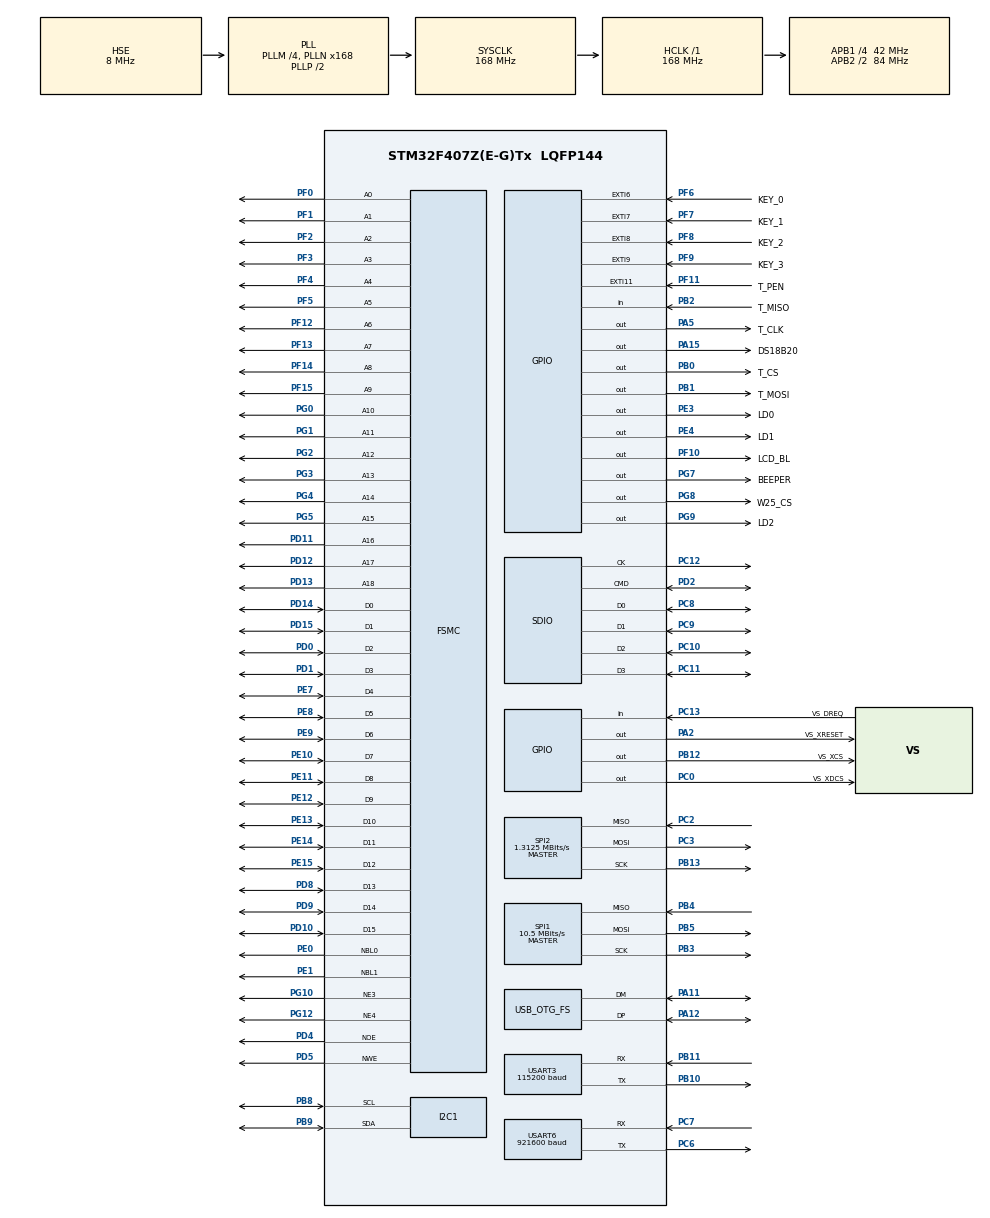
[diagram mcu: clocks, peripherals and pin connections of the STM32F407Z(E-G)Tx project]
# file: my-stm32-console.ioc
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ADC1.Channel-0\#ChannelRegularConversion=ADC_CHANNEL_TEMPSENSOR
ADC1.NbrOfConversionFlag=1
ADC1.Rank-0\#ChannelRegularConversion=1
ADC1.SamplingTime-0\#ChannelRegularConversion=ADC_SAMPLETIME_480CYCLES
ADC1.master=1
Dma.MEMTOMEM.0.Direction=DMA_MEMORY_TO_MEMORY
Dma.MEMTOMEM.0.FIFOMode=DMA_FIFOMODE_ENABLE
Dma.MEMTOMEM.0.FIFOThreshold=DMA_FIFO_THRESHOLD_FULL
Dma.MEMTOMEM.0.Instance=DMA2_Stream0
Dma.MEMTOMEM.0.MemBurst=DMA_MBURST_SINGLE
Dma.MEMTOMEM.0.MemDataAlignment=DMA_MDATAALIGN_HALFWORD
Dma.MEMTOMEM.0.MemInc=DMA_MINC_DISABLE
Dma.MEMTOMEM.0.Mode=DMA_NORMAL
Dma.MEMTOMEM.0.PeriphBurst=DMA_PBURST_SINGLE
Dma.MEMTOMEM.0.PeriphDataAlignment=DMA_PDATAALIGN_HALFWORD
Dma.MEMTOMEM.0.PeriphInc=DMA_PINC_ENABLE
Dma.MEMTOMEM.0.Priority=DMA_PRIORITY_LOW
Dma.Request0=MEMTOMEM
Dma.Request1=SDIO_RX
Dma.Request2=SDIO_TX
Dma.Request3=USART6_RX
Dma.Request4=USART6_TX
Dma.Request5=SPI2_TX
Dma.SDIO_RX.1.Direction=DMA_PERIPH_TO_MEMORY
Dma.SDIO_RX.1.FIFOMode=DMA_FIFOMODE_ENABLE
Dma.SDIO_RX.1.FIFOThreshold=DMA_FIFO_THRESHOLD_FULL
Dma.SDIO_RX.1.Instance=DMA2_Stream3
Dma.SDIO_RX.1.MemBurst=DMA_MBURST_INC4
Dma.SDIO_RX.1.MemDataAlignment=DMA_MDATAALIGN_WORD
Dma.SDIO_RX.1.MemInc=DMA_MINC_ENABLE
Dma.SDIO_RX.1.Mode=DMA_PFCTRL
Dma.SDIO_RX.1.PeriphBurst=DMA_PBURST_INC4
Dma.SDIO_RX.1.PeriphDataAlignment=DMA_PDATAALIGN_WORD
Dma.SDIO_RX.1.PeriphInc=DMA_PINC_DISABLE
Dma.SDIO_RX.1.Priority=DMA_PRIORITY_VERY_HIGH
Dma.SDIO_TX.2.Direction=DMA_MEMORY_TO_PERIPH
Dma.SDIO_TX.2.FIFOMode=DMA_FIFOMODE_ENABLE
Dma.SDIO_TX.2.FIFOThreshold=DMA_FIFO_THRESHOLD_FULL
Dma.SDIO_TX.2.Instance=DMA2_Stream6
Dma.SDIO_TX.2.MemBurst=DMA_MBURST_INC4
Dma.SDIO_TX.2.MemDataAlignment=DMA_MDATAALIGN_WORD
Dma.SDIO_TX.2.MemInc=DMA_MINC_ENABLE
Dma.SDIO_TX.2.Mode=DMA_PFCTRL
Dma.SDIO_TX.2.PeriphBurst=DMA_PBURST_INC4
Dma.SDIO_TX.2.PeriphDataAlignment=DMA_PDATAALIGN_WORD
Dma.SDIO_TX.2.PeriphInc=DMA_PINC_DISABLE
Dma.SDIO_TX.2.Priority=DMA_PRIORITY_VERY_HIGH
Dma.SPI2_TX.5.Direction=DMA_MEMORY_TO_PERIPH
Dma.SPI2_TX.5.FIFOMode=DMA_FIFOMODE_DISABLE
Dma.SPI2_TX.5.Instance=DMA1_Stream4
Dma.SPI2_TX.5.MemDataAlignment=DMA_MDATAALIGN_BYTE
Dma.SPI2_TX.5.MemInc=DMA_MINC_ENABLE
Dma.SPI2_TX.5.Mode=DMA_NORMAL
Dma.SPI2_TX.5.PeriphDataAlignment=DMA_PDATAALIGN_BYTE
Dma.SPI2_TX.5.PeriphInc=DMA_PINC_DISABLE
Dma.SPI2_TX.5.Priority=DMA_PRIORITY_LOW
Dma.USART6_RX.3.Direction=DMA_PERIPH_TO_MEMORY
Dma.USART6_RX.3.FIFOMode=DMA_FIFOMODE_DISABLE
Dma.USART6_RX.3.Instance=DMA2_Stream1
Dma.USART6_RX.3.MemDataAlignment=DMA_MDATAALIGN_BYTE
Dma.USART6_RX.3.MemInc=DMA_MINC_ENABLE
Dma.USART6_RX.3.Mode=DMA_CIRCULAR
Dma.USART6_RX.3.PeriphDataAlignment=DMA_PDATAALIGN_BYTE
Dma.USART6_RX.3.PeriphInc=DMA_PINC_DISABLE
Dma.USART6_RX.3.Priority=DMA_PRIORITY_HIGH
Dma.USART6_TX.4.Direction=DMA_MEMORY_TO_PERIPH
Dma.USART6_TX.4.FIFOMode=DMA_FIFOMODE_DISABLE
Dma.USART6_TX.4.Instance=DMA2_Stream7
Dma.USART6_TX.4.MemDataAlignment=DMA_MDATAALIGN_BYTE
Dma.USART6_TX.4.MemInc=DMA_MINC_ENABLE
Dma.USART6_TX.4.Mode=DMA_NORMAL
Dma.USART6_TX.4.PeriphDataAlignment=DMA_PDATAALIGN_BYTE
Dma.USART6_TX.4.PeriphInc=DMA_PINC_DISABLE
Dma.USART6_TX.4.Priority=DMA_PRIORITY_MEDIUM
FATFS._FS_LOCK=8
FATFS._USE_LFN=2
FREERTOS.HEAP_NUMBER=5
FREERTOS.Tasks01=defaultTask,24,1024,StartDefaultTask,Default,NULL,Dynamic,NULL,NULL
FREERTOS.configCHECK_FOR_STACK_OVERFLOW=2
FREERTOS.configENABLE_FPU=1
FREERTOS.configGENERATE_RUN_TIME_STATS=1
FREERTOS.configUSE_APPLICATION_TASK_TAG=1
FREERTOS.configUSE_STATS_FORMATTING_FUNCTIONS=1
FSMC.AddressSetupTime1=2
FSMC.AddressSetupTime3=3
FSMC.BusTurnAroundDuration1=3
FSMC.BusTurnAroundDuration3=3
FSMC.DataSetupTime1=6
FSMC.DataSetupTime3=12
FSMC.WriteOperation3=FSMC_WRITE_OPERATION_ENABLE
IWDG.Prescaler=IWDG_PRESCALER_32
IWDG.Reload=4095
Mcu.Family=STM32F4
Mcu.Name=STM32F407Z(E-G)Tx
Mcu.Package=LQFP144
NVIC.DMA1_Stream4_IRQn=true\:5\:0\:false\:false\:true\:true\:false\:true\:true
NVIC.DMA2_Stream0_IRQn=true\:5\:0\:false\:false\:true\:true\:true\:true\:true
NVIC.DMA2_Stream1_IRQn=true\:5\:0\:false\:false\:true\:true\:false\:true\:true
NVIC.DMA2_Stream3_IRQn=true\:5\:0\:false\:false\:true\:true\:false\:true\:true
NVIC.DMA2_Stream6_IRQn=true\:5\:0\:false\:false\:true\:true\:false\:true\:true
NVIC.DMA2_Stream7_IRQn=true\:5\:0\:false\:false\:true\:true\:false\:true\:true
NVIC.EXTI15_10_IRQn=true\:5\:0\:false\:false\:true\:true\:true\:true\:true
NVIC.EXTI9_5_IRQn=true\:5\:0\:false\:false\:true\:true\:true\:false\:true
NVIC.OTG_FS_IRQn=true\:6\:0\:true\:false\:true\:true\:true\:true\:true
NVIC.PriorityGroup=NVIC_PRIORITYGROUP_4
NVIC.SDIO_IRQn=true\:5\:0\:false\:false\:true\:true\:true\:true\:true
NVIC.TIM4_IRQn=true\:1\:0\:true\:false\:true\:false\:false\:true\:true
NVIC.TimeBase=TIM4_IRQn
NVIC.TimeBaseIP=TIM4
NVIC.USART3_IRQn=true\:5\:0\:false\:false\:true\:true\:true\:true\:true
NVIC.USART6_IRQn=true\:5\:0\:false\:false\:true\:true\:true\:true\:true
PA11.Mode=Host_Only
PA11.Signal=USB_OTG_FS_DM
PA12.Mode=Host_Only
PA12.Signal=USB_OTG_FS_DP
PA13.Mode=Serial_Wire
PA13.Signal=SYS_JTMS-SWDIO
PA14.Mode=Serial_Wire
PA14.Signal=SYS_JTCK-SWCLK
PA15.GPIO_Label=DS18B20
PA15.Signal=GPIO_Output
PA2.GPIO_Label=VS_XRESET
PA2.Signal=GPIO_Output
PA5.GPIO_Label=T_CLK
PA5.PinState=GPIO_PIN_SET
PA5.Signal=GPIO_Output
PB0.GPIO_Label=T_CS
PB0.PinState=GPIO_PIN_SET
PB0.Signal=GPIO_Output
PB1.GPIO_Label=T_MOSI
PB1.PinState=GPIO_PIN_SET
PB1.Signal=GPIO_Output
PB10.Mode=Asynchronous
PB10.Signal=USART3_TX
PB11.Mode=Asynchronous
PB11.Signal=USART3_RX
PB12.GPIO_Label=VS_XCS
PB12.GPIO_Speed=GPIO_SPEED_FREQ_HIGH
PB12.PinState=GPIO_PIN_SET
PB12.Signal=GPIO_Output
PB13.Mode=Full_Duplex_Master
PB13.Signal=SPI2_SCK
PB2.GPIO_Label=T_MISO
PB2.GPIO_PuPd=GPIO_PULLUP
PB2.Signal=GPIO_Input
PB3.Mode=Full_Duplex_Master
PB3.Signal=SPI1_SCK
PB4.Mode=Full_Duplex_Master
PB4.Signal=SPI1_MISO
PB5.Mode=Full_Duplex_Master
PB5.Signal=SPI1_MOSI
PB8.Mode=I2C
PB8.Signal=I2C1_SCL
PB9.Mode=I2C
PB9.Signal=I2C1_SDA
PC0.GPIO_Label=VS_XDCS
PC0.GPIO_Speed=GPIO_SPEED_FREQ_HIGH
PC0.PinState=GPIO_PIN_SET
PC0.Signal=GPIO_Output
PC10.Mode=SD_4_bits_Wide_bus
PC10.Signal=SDIO_D2
PC11.Mode=SD_4_bits_Wide_bus
PC11.Signal=SDIO_D3
PC12.Mode=SD_4_bits_Wide_bus
PC12.Signal=SDIO_CK
PC13-ANTI_TAMP.GPIO_Label=VS_DREQ
PC13-ANTI_TAMP.GPIO_PuPd=GPIO_PULLDOWN
PC13-ANTI_TAMP.Signal=GPIO_Input
PC14-OSC32_IN.Mode=LSE-External-Oscillator
PC14-OSC32_IN.Signal=RCC_OSC32_IN
PC15-OSC32_OUT.Mode=LSE-External-Oscillator
PC15-OSC32_OUT.Signal=RCC_OSC32_OUT
PC2.Mode=Full_Duplex_Master
PC2.Signal=SPI2_MISO
PC3.Mode=Full_Duplex_Master
PC3.Signal=SPI2_MOSI
PC6.GPIO_PuPd=GPIO_PULLUP
PC6.Mode=Asynchronous
PC6.Signal=USART6_TX
PC7.GPIO_PuPd=GPIO_PULLUP
PC7.Mode=Asynchronous
PC7.Signal=USART6_RX
PC8.Mode=SD_4_bits_Wide_bus
PC8.Signal=SDIO_D0
PC9.Mode=SD_4_bits_Wide_bus
PC9.Signal=SDIO_D1
PD0.Signal=FSMC_D2_DA2
PD1.Signal=FSMC_D3_DA3
PD10.Signal=FSMC_D15_DA15
PD11.Signal=FSMC_A16_CLE
PD12.Signal=FSMC_A17_ALE
PD13.Signal=FSMC_A18
PD14.Signal=FSMC_D0_DA0
PD15.Signal=FSMC_D1_DA1
PD2.Mode=SD_4_bits_Wide_bus
PD2.Signal=SDIO_CMD
PD4.Signal=FSMC_NOE
PD5.Signal=FSMC_NWE
PD8.Signal=FSMC_D13_DA13
PD9.Signal=FSMC_D14_DA14
PE0.Signal=FSMC_NBL0
PE1.Signal=FSMC_NBL1
PE10.Signal=FSMC_D7_DA7
PE11.Signal=FSMC_D8_DA8
PE12.Signal=FSMC_D9_DA9
PE13.Signal=FSMC_D10_DA10
PE14.Signal=FSMC_D11_DA11
PE15.Signal=FSMC_D12_DA12
PE3.GPIO_Label=LD0
PE3.PinState=GPIO_PIN_SET
PE3.Signal=GPIO_Output
PE4.GPIO_Label=LD1
PE4.PinState=GPIO_PIN_SET
PE4.Signal=GPIO_Output
PE7.Signal=FSMC_D4_DA4
PE8.Signal=FSMC_D5_DA5
PE9.Signal=FSMC_D6_DA6
PF0.Signal=FSMC_A0
PF1.Signal=FSMC_A1
PF10.GPIO_Label=LCD_BL
PF10.Signal=GPIO_Output
PF11.GPIO_Label=T_PEN
PF11.GPIO_ModeDefaultEXTI=GPIO_MODE_IT_RISING_FALLING
PF11.GPIO_PuPd=GPIO_PULLUP
PF11.Signal=GPXTI11
PF12.Signal=FSMC_A6
PF13.Signal=FSMC_A7
PF14.Signal=FSMC_A8
PF15.Signal=FSMC_A9
PF2.Signal=FSMC_A2
PF3.Signal=FSMC_A3
PF4.Signal=FSMC_A4
PF5.Signal=FSMC_A5
PF6.GPIO_Label=KEY_0
PF6.GPIO_ModeDefaultEXTI=GPIO_MODE_IT_FALLING
PF6.GPIO_PuPd=GPIO_PULLUP
PF6.Signal=GPXTI6
PF7.GPIO_Label=KEY_1
PF7.GPIO_ModeDefaultEXTI=GPIO_MODE_IT_FALLING
PF7.GPIO_PuPd=GPIO_PULLUP
PF7.Signal=GPXTI7
PF8.GPIO_Label=KEY_2
PF8.GPIO_ModeDefaultEXTI=GPIO_MODE_IT_FALLING
PF8.GPIO_PuPd=GPIO_PULLUP
PF8.Signal=GPXTI8
PF9.GPIO_Label=KEY_3
PF9.GPIO_ModeDefaultEXTI=GPIO_MODE_IT_FALLING
PF9.GPIO_PuPd=GPIO_PULLUP
PF9.Signal=GPXTI9
PG0.Signal=FSMC_A10
PG1.Signal=FSMC_A11
PG10.Mode=NorPsramChipSelect3_3
PG10.Signal=FSMC_NE3
PG12.Mode=NorPsramChipSelect4_1
PG12.Signal=FSMC_NE4
PG2.Signal=FSMC_A12
PG3.Signal=FSMC_A13
PG4.Signal=FSMC_A14
PG5.Signal=FSMC_A15
PG7.GPIO_Label=BEEPER
PG7.GPIO_Speed=GPIO_SPEED_FREQ_HIGH
PG7.PinState=GPIO_PIN_RESET
PG7.Signal=GPIO_Output
PG8.GPIO_Label=W25_CS
PG8.PinState=GPIO_PIN_SET
PG8.Signal=GPIO_Output
PG9.GPIO_Label=LD2
PG9.PinState=GPIO_PIN_SET
PG9.Signal=GPIO_Output
PH0-OSC_IN.Mode=HSE-External-Oscillator
PH0-OSC_IN.Signal=RCC_OSC_IN
PH1-OSC_OUT.Mode=HSE-External-Oscillator
PH1-OSC_OUT.Signal=RCC_OSC_OUT
ProjectManager.HeapSize=0x200
ProjectManager.StackSize=0x400
ProjectManager.TargetToolchain=CMake
RCC.48MHZClocksFreq_Value=48000000
RCC.AHBFreq_Value=168000000
RCC.APB1CLKDivider=RCC_HCLK_DIV4
RCC.APB1Freq_Value=42000000
RCC.APB1TimFreq_Value=84000000
RCC.APB2CLKDivider=RCC_HCLK_DIV2
RCC.APB2Freq_Value=84000000
RCC.APB2TimFreq_Value=168000000
RCC.CortexFreq_Value=168000000
RCC.HCLKFreq_Value=168000000
RCC.HSE_VALUE=8000000
RCC.HSI_VALUE=16000000
RCC.PLLM=4
RCC.PLLN=168
RCC.PLLQ=7
RCC.RCC_RTC_Clock_Source=RCC_RTCCLKSOURCE_LSE
RCC.RCC_RTC_Clock_SourceVirtual=RCC_RTCCLKSOURCE_LSE
RCC.SYSCLKFreq_VALUE=168000000
RCC.SYSCLKSource=RCC_SYSCLKSOURCE_PLLCLK
RCC.VCOOutputFreq_Value=336000000
SDIO.ClockDiv=4
SH.FSMC_A0.0=FSMC_A0,19b-a3
SH.FSMC_A1.0=FSMC_A1,19b-a3
SH.FSMC_A10.0=FSMC_A10,19b-a3
SH.FSMC_A11.0=FSMC_A11,19b-a3
SH.FSMC_A12.0=FSMC_A12,A12_1
SH.FSMC_A12.1=FSMC_A12,19b-a3
SH.FSMC_A13.0=FSMC_A13,19b-a3
SH.FSMC_A14.0=FSMC_A14,19b-a3
SH.FSMC_A15.0=FSMC_A15,19b-a3
SH.FSMC_A16_CLE.0=FSMC_A16,19b-a3
SH.FSMC_A17_ALE.0=FSMC_A17,19b-a3
SH.FSMC_A18.0=FSMC_A18,19b-a3
SH.FSMC_A2.0=FSMC_A2,19b-a3
SH.FSMC_A3.0=FSMC_A3,19b-a3
SH.FSMC_A4.0=FSMC_A4,19b-a3
SH.FSMC_A5.0=FSMC_A5,19b-a3
SH.FSMC_A6.0=FSMC_A6,19b-a3
SH.FSMC_A7.0=FSMC_A7,19b-a3
SH.FSMC_A8.0=FSMC_A8,19b-a3
SH.FSMC_A9.0=FSMC_A9,19b-a3
SH.FSMC_D0_DA0.0=FSMC_D0,16b-d1
SH.FSMC_D0_DA0.1=FSMC_D0,16b-d3
SH.FSMC_D10_DA10.0=FSMC_D10,16b-d1
SH.FSMC_D10_DA10.1=FSMC_D10,16b-d3
SH.FSMC_D11_DA11.0=FSMC_D11,16b-d1
SH.FSMC_D11_DA11.1=FSMC_D11,16b-d3
SH.FSMC_D12_DA12.0=FSMC_D12,16b-d1
SH.FSMC_D12_DA12.1=FSMC_D12,16b-d3
SH.FSMC_D13_DA13.0=FSMC_D13,16b-d1
SH.FSMC_D13_DA13.1=FSMC_D13,16b-d3
SH.FSMC_D14_DA14.0=FSMC_D14,16b-d1
SH.FSMC_D14_DA14.1=FSMC_D14,16b-d3
SH.FSMC_D15_DA15.0=FSMC_D15,16b-d1
SH.FSMC_D15_DA15.1=FSMC_D15,16b-d3
SH.FSMC_D1_DA1.0=FSMC_D1,16b-d1
SH.FSMC_D1_DA1.1=FSMC_D1,16b-d3
SH.FSMC_D2_DA2.0=FSMC_D2,16b-d1
SH.FSMC_D2_DA2.1=FSMC_D2,16b-d3
SH.FSMC_D3_DA3.0=FSMC_D3,16b-d1
SH.FSMC_D3_DA3.1=FSMC_D3,16b-d3
SH.FSMC_D4_DA4.0=FSMC_D4,16b-d1
SH.FSMC_D4_DA4.1=FSMC_D4,16b-d3
SH.FSMC_D5_DA5.0=FSMC_D5,16b-d1
SH.FSMC_D5_DA5.1=FSMC_D5,16b-d3
SH.FSMC_D6_DA6.0=FSMC_D6,16b-d1
SH.FSMC_D6_DA6.1=FSMC_D6,16b-d3
SH.FSMC_D7_DA7.0=FSMC_D7,16b-d1
SH.FSMC_D7_DA7.1=FSMC_D7,16b-d3
SH.FSMC_D8_DA8.0=FSMC_D8,16b-d1
SH.FSMC_D8_DA8.1=FSMC_D8,16b-d3
SH.FSMC_D9_DA9.0=FSMC_D9,16b-d1
SH.FSMC_D9_DA9.1=FSMC_D9,16b-d3
SH.FSMC_NBL0.0=FSMC_NBL0,2ByteEnable3
SH.FSMC_NBL1.0=FSMC_NBL1,2ByteEnable3
SH.FSMC_NOE.0=FSMC_NOE,Lcd1
SH.FSMC_NOE.1=FSMC_NOE,Sram3
SH.FSMC_NWE.0=FSMC_NWE,Lcd1
SH.FSMC_NWE.1=FSMC_NWE,Sram3
SPI1.BaudRatePrescaler=SPI_BAUDRATEPRESCALER_8
SPI1.CalculateBaudRate=10.5 MBits/s
SPI1.Direction=SPI_DIRECTION_2LINES
SPI1.Mode=SPI_MODE_MASTER
SPI1.VirtualType=VM_MASTER
SPI2.BaudRatePrescaler=SPI_BAUDRATEPRESCALER_32
SPI2.CalculateBaudRate=1.3125 MBits/s
SPI2.Direction=SPI_DIRECTION_2LINES
SPI2.Mode=SPI_MODE_MASTER
SPI2.VirtualType=VM_MASTER
TIM5.AutoReloadPreload=TIM_AUTORELOAD_PRELOAD_ENABLE
TIM5.Prescaler=83
USART3.BaudRate=115200
USART3.VirtualMode=VM_ASYNC
USART6.BaudRate=921600
USART6.VirtualMode=VM_ASYNC
USB_OTG_FS.VirtualMode=Host_Only
USB_OTG_FS.phy_itface=HCD_PHY_EMBEDDED
VP_ADC1_TempSens_Input.Mode=IN-TempSens
VP_ADC1_Vref_Input.Mode=IN-Vrefint
VP_CRC_VS_CRC.Mode=CRC_Activate
VP_FATFS_VS_SDIO.Mode=SDIO
VP_FREERTOS_VS_CMSIS_V2.Mode=CMSIS_V2
VP_IWDG_VS_IWDG.Mode=IWDG_Activate
VP_RTC_VS_RTC_Activate.Mode=RTC_Enabled
VP_RTC_VS_RTC_Calendar.Mode=RTC_Calendar
VP_SYS_VS_tim4.Mode=TIM4
VP_TIM5_VS_ClockSourceINT.Mode=Internal
board=custom

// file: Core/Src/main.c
/* USER CODE BEGIN Header */
/**
  ******************************************************************************
  * @file           : main.c
  * @brief          : Main program body
  ******************************************************************************
  * @attention
  *
  * Copyright (c) 2026 STMicroelectronics.
  * All rights reserved.
  *
  * This software is licensed under terms that can be found in the LICENSE file
  * in the root directory of this software component.
  * If no LICENSE file comes with this software, it is provided AS-IS.
  *
  ******************************************************************************
  */
/* USER CODE END Header */
#include "main.h"
#include "cmsis_os.h"
#include "fatfs.h"

/* USER CODE BEGIN Includes */
#include <stdio.h>
#include "ili9341_simple.h"
#include "XPT2046_touch.h"
#include "AT24Cxx.h"
#include "w25qxx.h"
#include <string.h>
#include "lvgl.h"
#include "lv_port_console.h"
#include "status_led.h"
#include "buttons_manager.h"
#include "beeper.h"
#include "system_post.h"
#include "sram_ext.h"
#include "sdcard_fatfs.h"
#include "usb_host_manager.h"
#include "os_tasks.h"
#include "ui_manager.h"
#include "app_loader.h"
#include "uart_loader.h"
#include "uart_cli.h"
#include "temp_sensor.h"
#include "vs1053.h"
#include "audio_player.h"
#include "audio_service.h"
#include "esp_companion.h"
#include "ccmram.h"
/* USER CODE END Includes */

/* USER CODE BEGIN PD */
/* Memory parameters for Step 2 */
#define INTERNAL_HEAP_SIZE    (configTOTAL_HEAP_SIZE)   /* According to the CubeMX settings */
#define EXTERNAL_SRAM_BASE    (0x68000000UL)            /* Bank 3's main address */
#define EXTERNAL_SRAM_SIZE    (1024 * 1024)             /* 1 megabyte */
/* USER CODE END PD */

ADC_HandleTypeDef hadc1;

CRC_HandleTypeDef hcrc;

I2C_HandleTypeDef hi2c1;

IWDG_HandleTypeDef hiwdg;

RTC_HandleTypeDef hrtc;

SD_HandleTypeDef hsd;
DMA_HandleTypeDef hdma_sdio_rx;
DMA_HandleTypeDef hdma_sdio_tx;

SPI_HandleTypeDef hspi1;
SPI_HandleTypeDef hspi2;
DMA_HandleTypeDef hdma_spi2_tx;

TIM_HandleTypeDef htim5;

UART_HandleTypeDef huart3;
UART_HandleTypeDef huart6;
DMA_HandleTypeDef hdma_usart6_rx;
DMA_HandleTypeDef hdma_usart6_tx;

HCD_HandleTypeDef hhcd_USB_OTG_FS;

DMA_HandleTypeDef hdma_memtomem_dma2_stream0;
SRAM_HandleTypeDef hsram1;
SRAM_HandleTypeDef hsram3;

/* Definitions for defaultTask */
osThreadId_t defaultTaskHandle;
const osThreadAttr_t defaultTask_attributes = {
  .name = "defaultTask",
  .stack_size = 1024 * 4,
  .priority = (osPriority_t) osPriorityNormal,
};
/* USER CODE BEGIN PV */
/* Internal part of the heap in CCM: task stacks and RTOS objects must never be DMA targets */
CCMRAM_BUF uint8_t ucHeapInternal[INTERNAL_HEAP_SIZE];
/* Region Configuration for Heap_5 (regions sorted by address) */
const HeapRegion_t xHeapRegions[] = {
    { ucHeapInternal, INTERNAL_HEAP_SIZE },                          // Region 1: CCM RAM
    { (uint8_t *)MM_EXT_OS_HEAP_BASE, MM_EXT_OS_HEAP_SIZE },         // Region 2: External SRAM 0x68040000..0x6807FFFF
    { NULL, 0 }                                                      // The Terminator
};

/* Framebuffer in External SRAM (Bank 3) */
uint16_t *frame_buffer = NULL; // It will be allocated via the FreeRTOS heap

/* App sandbox bounds defined only in linker/STM32F407ZG_console.ld */
extern uint8_t _sapp_ram[];
extern uint8_t _eapp_ram[];

/* .ccmram is NOLOAD and not touched by the startup code */
extern uint8_t _sccmram[];
extern uint8_t _eccmram[];
/* USER CODE END PV */

void SystemClock_Config(void);
static void MX_GPIO_Init(void);
static void MX_DMA_Init(void);
static void MX_CRC_Init(void);
static void MX_FSMC_Init(void);
static void MX_USART3_UART_Init(void);
static void MX_I2C1_Init(void);
static void MX_SPI1_Init(void);
static void MX_SDIO_SD_Init(void);
static void MX_USB_OTG_FS_HCD_Init(void);
static void MX_RTC_Init(void);
static void MX_IWDG_Init(void);
static void MX_TIM5_Init(void);
static void MX_ADC1_Init(void);
static void MX_USART6_UART_Init(void);
static void MX_SPI2_Init(void);
void StartDefaultTask(void *argument);

/* USER CODE BEGIN PFP */
void MPU_Config_UserSandbox(void);
/* USER CODE END PFP */

/* USER CODE BEGIN 0 */
/* Redirecting `printf` for GCC and Picolibc (CMake toolchain) */
int __io_putchar(int ch)
{
    if (!UARTLoader_IsSessionActive())
    {
        HAL_UART_Transmit(&huart3, (uint8_t *)&ch, 1, HAL_MAX_DELAY);
    }
    return ch;
}

int _write(int file, char *ptr, int len)
{
    (void)file;
    if (!UARTLoader_IsSessionActive())
    {
        HAL_UART_Transmit(&huart3, (uint8_t*) ptr, len, HAL_MAX_DELAY);
    }
    return len;
}

/* FreeRTOS RunTime Stats Timer Implementation using CubeMX-generated htim5 (32-bit) */
void configureTimerForRunTimeStats(void)
{
    HAL_TIM_Base_Start(&htim5);
}

unsigned long getRunTimeCounterValue(void)
{
    return (unsigned long)__HAL_TIM_GET_COUNTER(&htim5);
}
/* USER CODE END 0 */

int main(void)
{

  /* USER CODE BEGIN 1 */
  memset(_sccmram, 0, (size_t)(_eccmram - _sccmram));
  /* USER CODE END 1 */

  /* MCU Configuration--------------------------------------------------------*/

  /* Reset of all peripherals, Initializes the Flash interface and the Systick. */
  HAL_Init();

  /* Configure the system clock */
  SystemClock_Config();

  /* Initialize all configured peripherals */
  MX_GPIO_Init();
  MX_DMA_Init();
  MX_CRC_Init();
  MX_FSMC_Init();
  MX_USART3_UART_Init();
  MX_I2C1_Init();
  MX_SPI1_Init();
  MX_SDIO_SD_Init();
  MX_FATFS_Init();
  MX_USB_OTG_FS_HCD_Init();
  MX_RTC_Init();
  MX_IWDG_Init();
  MX_TIM5_Init();
  MX_ADC1_Init();
  MX_USART6_UART_Init();
  MX_SPI2_Init();
  /* USER CODE BEGIN 2 */

  if (((uint32_t)_sapp_ram != MM_APP_RAM_BASE) ||
      ((uint32_t)_eapp_ram != (MM_APP_RAM_BASE + MM_APP_RAM_SIZE)))
  {
    printf("[MEM] FATAL: linker APP_RAM does not match memory_map.h\r\n");
    Error_Handler();
  }

  // IMPORTANT: Configure and enable the MPU before the OS starts
  MPU_Config_UserSandbox();
  printf("MPU Sandbox Initialized.\r\n");

  // IMPORTANT: Let's initialize Heap_5 manually with our regions (Internal + External memory)
  vPortDefineHeapRegions(xHeapRegions);
  printf("Heap_5 Initialized Manually. Free: %u bytes\r\n", (unsigned int)xPortGetFreeHeapSize());
  printf("[MEM] App RAM   0x%08lX..0x%08lX (image %lu KB, stack %lu KB)\r\n",
         (unsigned long)MM_APP_RAM_BASE, (unsigned long)(MM_APP_RAM_BASE + MM_APP_RAM_SIZE - 1UL),
         (unsigned long)(MM_APP_IMAGE_MAX_SIZE / 1024UL), (unsigned long)(MM_APP_STACK_SIZE / 1024UL));
  printf("[MEM] LVGL pool 0x%08lX..0x%08lX (%lu KB)\r\n",
         (unsigned long)MM_EXT_LVGL_MEM_BASE, (unsigned long)(MM_EXT_LVGL_MEM_BASE + MM_EXT_LVGL_MEM_SIZE - 1UL),
         (unsigned long)(MM_EXT_LVGL_MEM_SIZE / 1024UL));
  printf("[MEM] OS heap   0x%08lX..0x%08lX\r\n",
         (unsigned long)MM_EXT_OS_HEAP_BASE, (unsigned long)(MM_EXT_OS_HEAP_BASE + MM_EXT_OS_HEAP_SIZE - 1UL));
  printf("[MEM] App ext   0x%08lX..0x%08lX\r\n",
         (unsigned long)MM_EXT_APP_BASE, (unsigned long)(MM_EXT_APP_BASE + MM_EXT_APP_SIZE - 1UL));
  /* USER CODE END 2 */

  /* Init scheduler */
  osKernelInitialize();

  /* Create the thread(s) */
  /* creation of defaultTask */
  defaultTaskHandle = osThreadNew(StartDefaultTask, NULL, &defaultTask_attributes);

  /* USER CODE BEGIN RTOS_THREADS */
  /* The unprivileged sandbox task is created per app launch by AppLoader_LoadAndRun() */
  /* USER CODE END RTOS_THREADS */

  /* Start scheduler */
  osKernelStart();

  /* We should never get here as control is now taken by the scheduler */

  /* Infinite loop */
  while (1)
  {

  }
}

void SystemClock_Config(void)
{
  RCC_OscInitTypeDef RCC_OscInitStruct = {0};
  RCC_ClkInitTypeDef RCC_ClkInitStruct = {0};

  /** Configure the main internal regulator output voltage
  */
  __HAL_RCC_PWR_CLK_ENABLE();
  __HAL_PWR_VOLTAGESCALING_CONFIG(PWR_REGULATOR_VOLTAGE_SCALE1);

  /** Initializes the RCC Oscillators according to the specified parameters
  * in the RCC_OscInitTypeDef structure.
  */
  RCC_OscInitStruct.OscillatorType = RCC_OSCILLATORTYPE_LSI|RCC_OSCILLATORTYPE_HSE
                              |RCC_OSCILLATORTYPE_LSE;
  RCC_OscInitStruct.HSEState = RCC_HSE_ON;
  RCC_OscInitStruct.LSEState = RCC_LSE_ON;
  RCC_OscInitStruct.LSIState = RCC_LSI_ON;
  RCC_OscInitStruct.PLL.PLLState = RCC_PLL_ON;
  RCC_OscInitStruct.PLL.PLLSource = RCC_PLLSOURCE_HSE;
  RCC_OscInitStruct.PLL.PLLM = 4;
  RCC_OscInitStruct.PLL.PLLN = 168;
  RCC_OscInitStruct.PLL.PLLP = RCC_PLLP_DIV2;
  RCC_OscInitStruct.PLL.PLLQ = 7;
  if (HAL_RCC_OscConfig(&RCC_OscInitStruct) != HAL_OK)
  {
    Error_Handler();
  }

  /** Initializes the CPU, AHB and APB buses clocks
  */
  RCC_ClkInitStruct.ClockType = RCC_CLOCKTYPE_HCLK|RCC_CLOCKTYPE_SYSCLK
                              |RCC_CLOCKTYPE_PCLK1|RCC_CLOCKTYPE_PCLK2;
  RCC_ClkInitStruct.SYSCLKSource = RCC_SYSCLKSOURCE_PLLCLK;
  RCC_ClkInitStruct.AHBCLKDivider = RCC_SYSCLK_DIV1;
  RCC_ClkInitStruct.APB1CLKDivider = RCC_HCLK_DIV4;
  RCC_ClkInitStruct.APB2CLKDivider = RCC_HCLK_DIV2;

  if (HAL_RCC_ClockConfig(&RCC_ClkInitStruct, FLASH_LATENCY_5) != HAL_OK)
  {
    Error_Handler();
  }
}

static void MX_ADC1_Init(void)
{

  ADC_ChannelConfTypeDef sConfig = {0};

  /** Configure the global features of the ADC (Clock, Resolution, Data Alignment and number of conversion)
  */
  hadc1.Instance = ADC1;
  hadc1.Init.ClockPrescaler = ADC_CLOCK_SYNC_PCLK_DIV4;
  hadc1.Init.Resolution = ADC_RESOLUTION_12B;
  hadc1.Init.ScanConvMode = DISABLE;
  hadc1.Init.ContinuousConvMode = DISABLE;
  hadc1.Init.DiscontinuousConvMode = DISABLE;
  hadc1.Init.ExternalTrigConvEdge = ADC_EXTERNALTRIGCONVEDGE_NONE;
  hadc1.Init.ExternalTrigConv = ADC_SOFTWARE_START;
  hadc1.Init.DataAlign = ADC_DATAALIGN_RIGHT;
  hadc1.Init.NbrOfConversion = 1;
  hadc1.Init.DMAContinuousRequests = DISABLE;
  hadc1.Init.EOCSelection = ADC_EOC_SINGLE_CONV;
  if (HAL_ADC_Init(&hadc1) != HAL_OK)
  {
    Error_Handler();
  }

  /** Configure for the selected ADC regular channel its corresponding rank in the sequencer and its sample time.
  */
  sConfig.Channel = ADC_CHANNEL_TEMPSENSOR;
  sConfig.Rank = 1;
  sConfig.SamplingTime = ADC_SAMPLETIME_480CYCLES;
  if (HAL_ADC_ConfigChannel(&hadc1, &sConfig) != HAL_OK)
  {
    Error_Handler();
  }

}

static void MX_CRC_Init(void)
{

  hcrc.Instance = CRC;
  if (HAL_CRC_Init(&hcrc) != HAL_OK)
  {
    Error_Handler();
  }

}

static void MX_I2C1_Init(void)
{

  hi2c1.Instance = I2C1;
  hi2c1.Init.ClockSpeed = 100000;
  hi2c1.Init.DutyCycle = I2C_DUTYCYCLE_2;
  hi2c1.Init.OwnAddress1 = 0;
  hi2c1.Init.AddressingMode = I2C_ADDRESSINGMODE_7BIT;
  hi2c1.Init.DualAddressMode = I2C_DUALADDRESS_DISABLE;
  hi2c1.Init.OwnAddress2 = 0;
  hi2c1.Init.GeneralCallMode = I2C_GENERALCALL_DISABLE;
  hi2c1.Init.NoStretchMode = I2C_NOSTRETCH_DISABLE;
  if (HAL_I2C_Init(&hi2c1) != HAL_OK)
  {
    Error_Handler();
  }

}

static void MX_IWDG_Init(void)
{

  hiwdg.Instance = IWDG;
  hiwdg.Init.Prescaler = IWDG_PRESCALER_32;
  hiwdg.Init.Reload = 4095;
  if (HAL_IWDG_Init(&hiwdg) != HAL_OK)
  {
    Error_Handler();
  }

}

static void MX_RTC_Init(void)
{

  RTC_TimeTypeDef sTime = {0};
  RTC_DateTypeDef sDate = {0};

  /** Initialize RTC Only
  */
  hrtc.Instance = RTC;
  hrtc.Init.HourFormat = RTC_HOURFORMAT_24;
  hrtc.Init.AsynchPrediv = 127;
  hrtc.Init.SynchPrediv = 255;
  hrtc.Init.OutPut = RTC_OUTPUT_DISABLE;
  hrtc.Init.OutPutPolarity = RTC_OUTPUT_POLARITY_HIGH;
  hrtc.Init.OutPutType = RTC_OUTPUT_TYPE_OPENDRAIN;
  if (HAL_RTC_Init(&hrtc) != HAL_OK)
  {
    Error_Handler();
  }

  /* USER CODE BEGIN Check_RTC_BKUP */
  /* If backup register already holds magic value 0x32F4, battery kept RTC alive:
  * skip resetting time/date to 00:00:00! */
  if (HAL_RTCEx_BKUPRead(&hrtc, RTC_BKP_DR0) == 0x32F4U)
  {
    return;
  }
  HAL_PWR_EnableBkUpAccess();
  HAL_RTCEx_BKUPWrite(&hrtc, RTC_BKP_DR0, 0x32F4U);
  /* USER CODE END Check_RTC_BKUP */

  /** Initialize RTC and set the Time and Date
  */
  sTime.Hours = 0x0;
  sTime.Minutes = 0x0;
  sTime.Seconds = 0x0;
  sTime.DayLightSaving = RTC_DAYLIGHTSAVING_NONE;
  sTime.StoreOperation = RTC_STOREOPERATION_RESET;
  if (HAL_RTC_SetTime(&hrtc, &sTime, RTC_FORMAT_BCD) != HAL_OK)
  {
    Error_Handler();
  }
  sDate.WeekDay = RTC_WEEKDAY_MONDAY;
  sDate.Month = RTC_MONTH_JANUARY;
  sDate.Date = 0x1;
  sDate.Year = 0x0;

  if (HAL_RTC_SetDate(&hrtc, &sDate, RTC_FORMAT_BCD) != HAL_OK)
  {
    Error_Handler();
  }

}

static void MX_SDIO_SD_Init(void)
{

  hsd.Instance = SDIO;
  hsd.Init.ClockEdge = SDIO_CLOCK_EDGE_RISING;
  hsd.Init.ClockBypass = SDIO_CLOCK_BYPASS_DISABLE;
  hsd.Init.ClockPowerSave = SDIO_CLOCK_POWER_SAVE_DISABLE;
  hsd.Init.BusWide = SDIO_BUS_WIDE_1B;
  hsd.Init.HardwareFlowControl = SDIO_HARDWARE_FLOW_CONTROL_DISABLE;
  hsd.Init.ClockDiv = 4;

}

static void MX_SPI1_Init(void)
{

  /* SPI1 parameter configuration*/
  hspi1.Instance = SPI1;
  hspi1.Init.Mode = SPI_MODE_MASTER;
  hspi1.Init.Direction = SPI_DIRECTION_2LINES;
  hspi1.Init.DataSize = SPI_DATASIZE_8BIT;
  hspi1.Init.CLKPolarity = SPI_POLARITY_LOW;
  hspi1.Init.CLKPhase = SPI_PHASE_1EDGE;
  hspi1.Init.NSS = SPI_NSS_SOFT;
  hspi1.Init.BaudRatePrescaler = SPI_BAUDRATEPRESCALER_8;
  hspi1.Init.FirstBit = SPI_FIRSTBIT_MSB;
  hspi1.Init.TIMode = SPI_TIMODE_DISABLE;
  hspi1.Init.CRCCalculation = SPI_CRCCALCULATION_DISABLE;
  hspi1.Init.CRCPolynomial = 10;
  if (HAL_SPI_Init(&hspi1) != HAL_OK)
  {
    Error_Handler();
  }

}

static void MX_SPI2_Init(void)
{

  /* SPI2 parameter configuration*/
  hspi2.Instance = SPI2;
  hspi2.Init.Mode = SPI_MODE_MASTER;
  hspi2.Init.Direction = SPI_DIRECTION_2LINES;
  hspi2.Init.DataSize = SPI_DATASIZE_8BIT;
  hspi2.Init.CLKPolarity = SPI_POLARITY_LOW;
  hspi2.Init.CLKPhase = SPI_PHASE_1EDGE;
  hspi2.Init.NSS = SPI_NSS_SOFT;
  hspi2.Init.BaudRatePrescaler = SPI_BAUDRATEPRESCALER_32;
  hspi2.Init.FirstBit = SPI_FIRSTBIT_MSB;
  hspi2.Init.TIMode = SPI_TIMODE_DISABLE;
  hspi2.Init.CRCCalculation = SPI_CRCCALCULATION_DISABLE;
  hspi2.Init.CRCPolynomial = 10;
  if (HAL_SPI_Init(&hspi2) != HAL_OK)
  {
    Error_Handler();
  }

}

static void MX_TIM5_Init(void)
{

  TIM_ClockConfigTypeDef sClockSourceConfig = {0};
  TIM_MasterConfigTypeDef sMasterConfig = {0};

  htim5.Instance = TIM5;
  htim5.Init.Prescaler = 83;
  htim5.Init.CounterMode = TIM_COUNTERMODE_UP;
  htim5.Init.Period = 4294967295;
  htim5.Init.ClockDivision = TIM_CLOCKDIVISION_DIV1;
  htim5.Init.AutoReloadPreload = TIM_AUTORELOAD_PRELOAD_ENABLE;
  if (HAL_TIM_Base_Init(&htim5) != HAL_OK)
  {
    Error_Handler();
  }
  sClockSourceConfig.ClockSource = TIM_CLOCKSOURCE_INTERNAL;
  if (HAL_TIM_ConfigClockSource(&htim5, &sClockSourceConfig) != HAL_OK)
  {
    Error_Handler();
  }
  sMasterConfig.MasterOutputTrigger = TIM_TRGO_RESET;
  sMasterConfig.MasterSlaveMode = TIM_MASTERSLAVEMODE_DISABLE;
  if (HAL_TIMEx_MasterConfigSynchronization(&htim5, &sMasterConfig) != HAL_OK)
  {
    Error_Handler();
  }

}

static void MX_USART3_UART_Init(void)
{

  huart3.Instance = USART3;
  huart3.Init.BaudRate = 115200;
  huart3.Init.WordLength = UART_WORDLENGTH_8B;
  huart3.Init.StopBits = UART_STOPBITS_1;
  huart3.Init.Parity = UART_PARITY_NONE;
  huart3.Init.Mode = UART_MODE_TX_RX;
  huart3.Init.HwFlowCtl = UART_HWCONTROL_NONE;
  huart3.Init.OverSampling = UART_OVERSAMPLING_16;
  if (HAL_UART_Init(&huart3) != HAL_OK)
  {
    Error_Handler();
  }

}

static void MX_USART6_UART_Init(void)
{

  huart6.Instance = USART6;
  huart6.Init.BaudRate = 921600;
  huart6.Init.WordLength = UART_WORDLENGTH_8B;
  huart6.Init.StopBits = UART_STOPBITS_1;
  huart6.Init.Parity = UART_PARITY_NONE;
  huart6.Init.Mode = UART_MODE_TX_RX;
  huart6.Init.HwFlowCtl = UART_HWCONTROL_NONE;
  huart6.Init.OverSampling = UART_OVERSAMPLING_16;
  if (HAL_UART_Init(&huart6) != HAL_OK)
  {
    Error_Handler();
  }

}

static void MX_USB_OTG_FS_HCD_Init(void)
{

  /* USER CODE BEGIN USB_OTG_FS_Init 0 */
  /* Initialize USB_OTG_FS GPIOs (PA11/PA12), Clock, and NVIC via CubeMX MSP,
   * then return immediately so TinyUSB (hcd_dwc2) owns the USB_OTG_FS registers! */
  hhcd_USB_OTG_FS.Instance = USB_OTG_FS;
  HAL_HCD_MspInit(&hhcd_USB_OTG_FS);
  return;
  /* USER CODE END USB_OTG_FS_Init 0 */

  hhcd_USB_OTG_FS.Instance = USB_OTG_FS;
  hhcd_USB_OTG_FS.Init.Host_channels = 8;
  hhcd_USB_OTG_FS.Init.speed = HCD_SPEED_FULL;
  hhcd_USB_OTG_FS.Init.dma_enable = DISABLE;
  hhcd_USB_OTG_FS.Init.phy_itface = HCD_PHY_EMBEDDED;
  hhcd_USB_OTG_FS.Init.Sof_enable = DISABLE;
  if (HAL_HCD_Init(&hhcd_USB_OTG_FS) != HAL_OK)
  {
    Error_Handler();
  }

}

static void MX_DMA_Init(void)
{

  /* DMA controller clock enable */
  __HAL_RCC_DMA2_CLK_ENABLE();
  __HAL_RCC_DMA1_CLK_ENABLE();

  /* Configure DMA request hdma_memtomem_dma2_stream0 on DMA2_Stream0 */
  hdma_memtomem_dma2_stream0.Instance = DMA2_Stream0;
  hdma_memtomem_dma2_stream0.Init.Channel = DMA_CHANNEL_0;
  hdma_memtomem_dma2_stream0.Init.Direction = DMA_MEMORY_TO_MEMORY;
  hdma_memtomem_dma2_stream0.Init.PeriphInc = DMA_PINC_ENABLE;
  hdma_memtomem_dma2_stream0.Init.MemInc = DMA_MINC_DISABLE;
  hdma_memtomem_dma2_stream0.Init.PeriphDataAlignment = DMA_PDATAALIGN_HALFWORD;
  hdma_memtomem_dma2_stream0.Init.MemDataAlignment = DMA_MDATAALIGN_HALFWORD;
  hdma_memtomem_dma2_stream0.Init.Mode = DMA_NORMAL;
  hdma_memtomem_dma2_stream0.Init.Priority = DMA_PRIORITY_LOW;
  hdma_memtomem_dma2_stream0.Init.FIFOMode = DMA_FIFOMODE_ENABLE;
  hdma_memtomem_dma2_stream0.Init.FIFOThreshold = DMA_FIFO_THRESHOLD_FULL;
  hdma_memtomem_dma2_stream0.Init.MemBurst = DMA_MBURST_SINGLE;
  hdma_memtomem_dma2_stream0.Init.PeriphBurst = DMA_PBURST_SINGLE;
  if (HAL_DMA_Init(&hdma_memtomem_dma2_stream0) != HAL_OK)
  {
    Error_Handler( );
  }

  /* DMA interrupt init */
  /* DMA1_Stream4_IRQn interrupt configuration */
  HAL_NVIC_SetPriority(DMA1_Stream4_IRQn, 5, 0);
  HAL_NVIC_EnableIRQ(DMA1_Stream4_IRQn);
  /* DMA2_Stream0_IRQn interrupt configuration */
  HAL_NVIC_SetPriority(DMA2_Stream0_IRQn, 5, 0);
  HAL_NVIC_EnableIRQ(DMA2_Stream0_IRQn);
  /* DMA2_Stream1_IRQn interrupt configuration */
  HAL_NVIC_SetPriority(DMA2_Stream1_IRQn, 5, 0);
  HAL_NVIC_EnableIRQ(DMA2_Stream1_IRQn);
  /* DMA2_Stream3_IRQn interrupt configuration */
  HAL_NVIC_SetPriority(DMA2_Stream3_IRQn, 5, 0);
  HAL_NVIC_EnableIRQ(DMA2_Stream3_IRQn);
  /* DMA2_Stream6_IRQn interrupt configuration */
  HAL_NVIC_SetPriority(DMA2_Stream6_IRQn, 5, 0);
  HAL_NVIC_EnableIRQ(DMA2_Stream6_IRQn);
  /* DMA2_Stream7_IRQn interrupt configuration */
  HAL_NVIC_SetPriority(DMA2_Stream7_IRQn, 5, 0);
  HAL_NVIC_EnableIRQ(DMA2_Stream7_IRQn);

}

static void MX_GPIO_Init(void)
{
  GPIO_InitTypeDef GPIO_InitStruct = {0};

  /* GPIO Ports Clock Enable */
  __HAL_RCC_GPIOE_CLK_ENABLE();
  __HAL_RCC_GPIOC_CLK_ENABLE();
  __HAL_RCC_GPIOF_CLK_ENABLE();
  __HAL_RCC_GPIOH_CLK_ENABLE();
  __HAL_RCC_GPIOA_CLK_ENABLE();
  __HAL_RCC_GPIOB_CLK_ENABLE();
  __HAL_RCC_GPIOG_CLK_ENABLE();
  __HAL_RCC_GPIOD_CLK_ENABLE();

  /*Configure GPIO pin Output Level */
  HAL_GPIO_WritePin(GPIOE, LD0_Pin|LD1_Pin, GPIO_PIN_SET);

  /*Configure GPIO pin Output Level */
  HAL_GPIO_WritePin(LCD_BL_GPIO_Port, LCD_BL_Pin, GPIO_PIN_RESET);

  /*Configure GPIO pin Output Level */
  HAL_GPIO_WritePin(VS_XDCS_GPIO_Port, VS_XDCS_Pin, GPIO_PIN_SET);

  /*Configure GPIO pin Output Level */
  HAL_GPIO_WritePin(GPIOA, VS_XRESET_Pin|DS18B20_Pin, GPIO_PIN_RESET);

  /*Configure GPIO pin Output Level */
  HAL_GPIO_WritePin(T_CLK_GPIO_Port, T_CLK_Pin, GPIO_PIN_SET);

  /*Configure GPIO pin Output Level */
  HAL_GPIO_WritePin(GPIOB, T_CS_Pin|T_MOSI_Pin|VS_XCS_Pin, GPIO_PIN_SET);

  /*Configure GPIO pin Output Level */
  HAL_GPIO_WritePin(BEEPER_GPIO_Port, BEEPER_Pin, GPIO_PIN_RESET);

  /*Configure GPIO pin Output Level */
  HAL_GPIO_WritePin(GPIOG, W25_CS_Pin|LD2_Pin, GPIO_PIN_SET);

  /*Configure GPIO pins : LD0_Pin LD1_Pin */
  GPIO_InitStruct.Pin = LD0_Pin|LD1_Pin;
  GPIO_InitStruct.Mode = GPIO_MODE_OUTPUT_PP;
  GPIO_InitStruct.Pull = GPIO_NOPULL;
  GPIO_InitStruct.Speed = GPIO_SPEED_FREQ_LOW;
  HAL_GPIO_Init(GPIOE, &GPIO_InitStruct);

  /*Configure GPIO pin : VS_DREQ_Pin */
  GPIO_InitStruct.Pin = VS_DREQ_Pin;
  GPIO_InitStruct.Mode = GPIO_MODE_INPUT;
  GPIO_InitStruct.Pull = GPIO_PULLDOWN;
  HAL_GPIO_Init(VS_DREQ_GPIO_Port, &GPIO_InitStruct);

  /*Configure GPIO pins : KEY_0_Pin KEY_1_Pin KEY_2_Pin KEY_3_Pin */
  GPIO_InitStruct.Pin = KEY_0_Pin|KEY_1_Pin|KEY_2_Pin|KEY_3_Pin;
  GPIO_InitStruct.Mode = GPIO_MODE_IT_FALLING;
  GPIO_InitStruct.Pull = GPIO_PULLUP;
  HAL_GPIO_Init(GPIOF, &GPIO_InitStruct);

  /*Configure GPIO pin : LCD_BL_Pin */
  GPIO_InitStruct.Pin = LCD_BL_Pin;
  GPIO_InitStruct.Mode = GPIO_MODE_OUTPUT_PP;
  GPIO_InitStruct.Pull = GPIO_NOPULL;
  GPIO_InitStruct.Speed = GPIO_SPEED_FREQ_LOW;
  HAL_GPIO_Init(LCD_BL_GPIO_Port, &GPIO_InitStruct);

  /*Configure GPIO pin : VS_XDCS_Pin */
  GPIO_InitStruct.Pin = VS_XDCS_Pin;
  GPIO_InitStruct.Mode = GPIO_MODE_OUTPUT_PP;
  GPIO_InitStruct.Pull = GPIO_NOPULL;
  GPIO_InitStruct.Speed = GPIO_SPEED_FREQ_HIGH;
  HAL_GPIO_Init(VS_XDCS_GPIO_Port, &GPIO_InitStruct);

  /*Configure GPIO pins : VS_XRESET_Pin T_CLK_Pin DS18B20_Pin */
  GPIO_InitStruct.Pin = VS_XRESET_Pin|T_CLK_Pin|DS18B20_Pin;
  GPIO_InitStruct.Mode = GPIO_MODE_OUTPUT_PP;
  GPIO_InitStruct.Pull = GPIO_NOPULL;
  GPIO_InitStruct.Speed = GPIO_SPEED_FREQ_LOW;
  HAL_GPIO_Init(GPIOA, &GPIO_InitStruct);

  /*Configure GPIO pins : T_CS_Pin T_MOSI_Pin */
  GPIO_InitStruct.Pin = T_CS_Pin|T_MOSI_Pin;
  GPIO_InitStruct.Mode = GPIO_MODE_OUTPUT_PP;
  GPIO_InitStruct.Pull = GPIO_NOPULL;
  GPIO_InitStruct.Speed = GPIO_SPEED_FREQ_LOW;
  HAL_GPIO_Init(GPIOB, &GPIO_InitStruct);

  /*Configure GPIO pin : T_MISO_Pin */
  GPIO_InitStruct.Pin = T_MISO_Pin;
  GPIO_InitStruct.Mode = GPIO_MODE_INPUT;
  GPIO_InitStruct.Pull = GPIO_PULLUP;
  HAL_GPIO_Init(T_MISO_GPIO_Port, &GPIO_InitStruct);

  /*Configure GPIO pin : T_PEN_Pin */
  GPIO_InitStruct.Pin = T_PEN_Pin;
  GPIO_InitStruct.Mode = GPIO_MODE_IT_RISING_FALLING;
  GPIO_InitStruct.Pull = GPIO_PULLUP;
  HAL_GPIO_Init(T_PEN_GPIO_Port, &GPIO_InitStruct);

  /*Configure GPIO pin : VS_XCS_Pin */
  GPIO_InitStruct.Pin = VS_XCS_Pin;
  GPIO_InitStruct.Mode = GPIO_MODE_OUTPUT_PP;
  GPIO_InitStruct.Pull = GPIO_NOPULL;
  GPIO_InitStruct.Speed = GPIO_SPEED_FREQ_HIGH;
  HAL_GPIO_Init(VS_XCS_GPIO_Port, &GPIO_InitStruct);

  /*Configure GPIO pin : BEEPER_Pin */
  GPIO_InitStruct.Pin = BEEPER_Pin;
  GPIO_InitStruct.Mode = GPIO_MODE_OUTPUT_PP;
  GPIO_InitStruct.Pull = GPIO_NOPULL;
  GPIO_InitStruct.Speed = GPIO_SPEED_FREQ_HIGH;
  HAL_GPIO_Init(BEEPER_GPIO_Port, &GPIO_InitStruct);

  /*Configure GPIO pins : W25_CS_Pin LD2_Pin */
  GPIO_InitStruct.Pin = W25_CS_Pin|LD2_Pin;
  GPIO_InitStruct.Mode = GPIO_MODE_OUTPUT_PP;
  GPIO_InitStruct.Pull = GPIO_NOPULL;
  GPIO_InitStruct.Speed = GPIO_SPEED_FREQ_LOW;
  HAL_GPIO_Init(GPIOG, &GPIO_InitStruct);

  /* EXTI interrupt init*/
  HAL_NVIC_SetPriority(KEY_0_EXTI_IRQn, 5, 0);
  HAL_NVIC_EnableIRQ(KEY_0_EXTI_IRQn);

  HAL_NVIC_SetPriority(T_PEN_EXTI_IRQn, 5, 0);
  HAL_NVIC_EnableIRQ(T_PEN_EXTI_IRQn);

}

/* FSMC initialization function */
static void MX_FSMC_Init(void)
{

  FSMC_NORSRAM_TimingTypeDef Timing = {0};

  /** Perform the SRAM1 memory initialization sequence
  */
  hsram1.Instance = FSMC_NORSRAM_DEVICE;
  hsram1.Extended = FSMC_NORSRAM_EXTENDED_DEVICE;
  /* hsram1.Init */
  hsram1.Init.NSBank = FSMC_NORSRAM_BANK4;
  hsram1.Init.DataAddressMux = FSMC_DATA_ADDRESS_MUX_DISABLE;
  hsram1.Init.MemoryType = FSMC_MEMORY_TYPE_SRAM;
  hsram1.Init.MemoryDataWidth = FSMC_NORSRAM_MEM_BUS_WIDTH_16;
  hsram1.Init.BurstAccessMode = FSMC_BURST_ACCESS_MODE_DISABLE;
  hsram1.Init.WaitSignalPolarity = FSMC_WAIT_SIGNAL_POLARITY_LOW;
  hsram1.Init.WrapMode = FSMC_WRAP_MODE_DISABLE;
  hsram1.Init.WaitSignalActive = FSMC_WAIT_TIMING_BEFORE_WS;
  hsram1.Init.WriteOperation = FSMC_WRITE_OPERATION_ENABLE;
  hsram1.Init.WaitSignal = FSMC_WAIT_SIGNAL_DISABLE;
  hsram1.Init.ExtendedMode = FSMC_EXTENDED_MODE_DISABLE;
  hsram1.Init.AsynchronousWait = FSMC_ASYNCHRONOUS_WAIT_DISABLE;
  hsram1.Init.WriteBurst = FSMC_WRITE_BURST_DISABLE;
  hsram1.Init.PageSize = FSMC_PAGE_SIZE_NONE;
  /* Timing */
  Timing.AddressSetupTime = 2;
  Timing.AddressHoldTime = 15;
  Timing.DataSetupTime = 6;
  Timing.BusTurnAroundDuration = 3;
  Timing.CLKDivision = 16;
  Timing.DataLatency = 17;
  Timing.AccessMode = FSMC_ACCESS_MODE_A;
  /* ExtTiming */

  if (HAL_SRAM_Init(&hsram1, &Timing, NULL) != HAL_OK)
  {
    Error_Handler( );
  }

  /** Perform the SRAM3 memory initialization sequence
  */
  hsram3.Instance = FSMC_NORSRAM_DEVICE;
  hsram3.Extended = FSMC_NORSRAM_EXTENDED_DEVICE;
  /* hsram3.Init */
  hsram3.Init.NSBank = FSMC_NORSRAM_BANK3;
  hsram3.Init.DataAddressMux = FSMC_DATA_ADDRESS_MUX_DISABLE;
  hsram3.Init.MemoryType = FSMC_MEMORY_TYPE_SRAM;
  hsram3.Init.MemoryDataWidth = FSMC_NORSRAM_MEM_BUS_WIDTH_16;
  hsram3.Init.BurstAccessMode = FSMC_BURST_ACCESS_MODE_DISABLE;
  hsram3.Init.WaitSignalPolarity = FSMC_WAIT_SIGNAL_POLARITY_LOW;
  hsram3.Init.WrapMode = FSMC_WRAP_MODE_DISABLE;
  hsram3.Init.WaitSignalActive = FSMC_WAIT_TIMING_BEFORE_WS;
  hsram3.Init.WriteOperation = FSMC_WRITE_OPERATION_ENABLE;
  hsram3.Init.WaitSignal = FSMC_WAIT_SIGNAL_DISABLE;
  hsram3.Init.ExtendedMode = FSMC_EXTENDED_MODE_DISABLE;
  hsram3.Init.AsynchronousWait = FSMC_ASYNCHRONOUS_WAIT_DISABLE;
  hsram3.Init.WriteBurst = FSMC_WRITE_BURST_DISABLE;
  hsram3.Init.PageSize = FSMC_PAGE_SIZE_NONE;
  /* Timing */
  Timing.AddressSetupTime = 3;
  Timing.AddressHoldTime = 15;
  Timing.DataSetupTime = 12;
  Timing.BusTurnAroundDuration = 3;
  Timing.CLKDivision = 16;
  Timing.DataLatency = 17;
  Timing.AccessMode = FSMC_ACCESS_MODE_A;
  /* ExtTiming */

  if (HAL_SRAM_Init(&hsram3, &Timing, NULL) != HAL_OK)
  {
    Error_Handler( );
  }

  /* USER CODE BEGIN FSMC_Init 2 */
  /* Fallback override if CubeMX .ioc timings are ever reset:
   * - Bank 3 (IS62WV51216BLL-55, tAA=55ns): ADDSET=3, DATAST=12 (89.3ns @ 168MHz), BUSTURN=3
   * - Bank 4 (ILI9341 LCD): ADDSET=2, DATAST=6, BUSTURN=3
   *
   * FSMC_Bank1->BTCR[5] = (FSMC_Bank1->BTCR[5] & ~(0xFFUL | (0xFFUL << 8) | (0x0FUL << 16))) |
   *                       (3UL << 0) | (12UL << 8) | (3UL << 16);
   * FSMC_Bank1->BTCR[7] = (FSMC_Bank1->BTCR[7] & ~(0xFFUL | (0xFFUL << 8) | (0x0FUL << 16))) |
   *                       (2UL << 0) | (6UL << 8) | (3UL << 16);
   * __DSB();
   */
  /* USER CODE END FSMC_Init 2 */
}

/* USER CODE BEGIN 4 */
_Static_assert(MM_APP_RAM_SIZE == (64UL * 1024UL), "MPU Region 2 size must match MM_APP_RAM_SIZE");
_Static_assert(MM_EXT_APP_SIZE == (512UL * 1024UL), "MPU Region 4 size must match MM_EXT_APP_SIZE");

void MPU_Config_UserSandbox(void)
{
  MPU_Region_InitTypeDef MPU_InitStruct = {0};

  // Turn off the MPU while configuring it
  HAL_MPU_Disable();

  // Region 0: Flash Memory (Code) - Read-only and executable
  MPU_InitStruct.Enable = MPU_REGION_ENABLE;
  MPU_InitStruct.Number = MPU_REGION_NUMBER0;
  MPU_InitStruct.BaseAddress = 0x08000000;
  MPU_InitStruct.Size = MPU_REGION_SIZE_1MB;
  MPU_InitStruct.SubRegionDisable = 0x0;
  MPU_InitStruct.TypeExtField = MPU_TEX_LEVEL0;
  MPU_InitStruct.AccessPermission = MPU_REGION_PRIV_RO_URO; // Read-only for all
  MPU_InitStruct.DisableExec = MPU_INSTRUCTION_ACCESS_ENABLE; // Executable
  MPU_InitStruct.IsShareable = MPU_ACCESS_NOT_SHAREABLE;
  MPU_InitStruct.IsCacheable = MPU_ACCESS_CACHEABLE;
  MPU_InitStruct.IsBufferable = MPU_ACCESS_NOT_BUFFERABLE;
  HAL_MPU_ConfigRegion(&MPU_InitStruct);

  // Region 1: Internal SRAM (kernel) - privileged only, never executable
  MPU_InitStruct.Enable           = MPU_REGION_ENABLE;
  MPU_InitStruct.Number           = MPU_REGION_NUMBER1;
  MPU_InitStruct.BaseAddress      = 0x20000000;
  MPU_InitStruct.Size             = MPU_REGION_SIZE_128KB;
  MPU_InitStruct.SubRegionDisable = 0x0;
  MPU_InitStruct.TypeExtField     = MPU_TEX_LEVEL0;
  MPU_InitStruct.AccessPermission = MPU_REGION_PRIV_RW;
  MPU_InitStruct.DisableExec      = MPU_INSTRUCTION_ACCESS_DISABLE;
  MPU_InitStruct.IsShareable      = MPU_ACCESS_NOT_SHAREABLE;
  MPU_InitStruct.IsCacheable      = MPU_ACCESS_CACHEABLE;
  MPU_InitStruct.IsBufferable     = MPU_ACCESS_NOT_BUFFERABLE;
  HAL_MPU_ConfigRegion(&MPU_InitStruct);

  // Region 2: App sandbox in internal SRAM (64 KB: 60 KB code+data+bss + 4 KB stack); overrides Region 1
  MPU_InitStruct.Number           = MPU_REGION_NUMBER2;
  MPU_InitStruct.BaseAddress      = MM_APP_RAM_BASE;
  MPU_InitStruct.Size             = MPU_REGION_SIZE_64KB;
  MPU_InitStruct.AccessPermission = MPU_REGION_FULL_ACCESS;
  MPU_InitStruct.DisableExec      = MPU_INSTRUCTION_ACCESS_ENABLE;
  HAL_MPU_ConfigRegion(&MPU_InitStruct);

  // Region 3: External SRAM (kernel buffers & heap) - Normal Non-Cacheable (TEX=1, C=0, B=0), privileged only
  MPU_InitStruct.Number           = MPU_REGION_NUMBER3;
  MPU_InitStruct.BaseAddress      = MM_EXT_BASE;
  MPU_InitStruct.Size             = MPU_REGION_SIZE_1MB;
  MPU_InitStruct.TypeExtField     = MPU_TEX_LEVEL1; // CRITICAL: Normal Memory (allows unaligned access!)
  MPU_InitStruct.AccessPermission = MPU_REGION_PRIV_RW;
  MPU_InitStruct.DisableExec      = MPU_INSTRUCTION_ACCESS_DISABLE;
  MPU_InitStruct.IsCacheable      = MPU_ACCESS_NOT_CACHEABLE;
  MPU_InitStruct.IsBufferable     = MPU_ACCESS_NOT_BUFFERABLE;
  HAL_MPU_ConfigRegion(&MPU_InitStruct);

  // Region 4: App data sandbox in external SRAM; overrides Region 3, no code fetch from FSMC
  MPU_InitStruct.Number           = MPU_REGION_NUMBER4;
  MPU_InitStruct.BaseAddress      = MM_EXT_APP_BASE;
  MPU_InitStruct.Size             = MPU_REGION_SIZE_512KB;
  MPU_InitStruct.AccessPermission = MPU_REGION_FULL_ACCESS;
  HAL_MPU_ConfigRegion(&MPU_InitStruct);

  // Region 5: CCM RAM (kernel stacks) - privileged only, never executable
  MPU_InitStruct.Number           = MPU_REGION_NUMBER5;
  MPU_InitStruct.BaseAddress      = 0x10000000;
  MPU_InitStruct.Size             = MPU_REGION_SIZE_64KB;
  MPU_InitStruct.TypeExtField     = MPU_TEX_LEVEL0;
  MPU_InitStruct.AccessPermission = MPU_REGION_PRIV_RW;
  MPU_InitStruct.IsCacheable      = MPU_ACCESS_CACHEABLE;
  HAL_MPU_ConfigRegion(&MPU_InitStruct);

  // Enable the MPU. The background region keeps peripherals accessible to privileged code only
  HAL_MPU_Enable(MPU_PRIVILEGED_DEFAULT);

  // Dedicated BusFault / UsageFault handlers (MemManage is enabled by HAL_MPU_Enable)
  SCB->SHCSR |= SCB_SHCSR_BUSFAULTENA_Msk | SCB_SHCSR_USGFAULTENA_Msk;
}

void HAL_GPIO_EXTI_Callback(uint16_t GPIO_Pin)
{
  /* Filter interrupts: process ONLY our 4 buttons KEY_0..KEY_3 */
  if (GPIO_Pin == KEY_0_Pin || GPIO_Pin == KEY_1_Pin || GPIO_Pin == KEY_2_Pin || GPIO_Pin == KEY_3_Pin)
  {
      Buttons_EXTI_Callback(GPIO_Pin);
  }
}
/* USER CODE END 4 */

void StartDefaultTask(void *argument)
{
  /* USER CODE BEGIN 5 */
  (void)argument;
  /* SVCall must stay unmasked (priority 0) until FreeRTOS issues 'svc 0' with BASEPRI set;
   * afterwards app syscalls run below all peripheral IRQs and above PendSV. */
  HAL_NVIC_SetPriority(SVCall_IRQn, 14U, 0U);

  printf("[OS] GuiRenderTask (DefaultTask) Started.\r\n");

  printf("\r\n----------------------------------------\r\n");
  printf("  STM32F407 Console OS - Multi-Tasking  \r\n");
  printf("----------------------------------------\r\n");

  USBHostManager_Init();
  printf("[INIT] USB Host Manager Ready.\r\n");

  uint32_t sys_freq = HAL_RCC_GetSysClockFreq();
  printf("System Clock Frequency: %lu MHz\r\n", sys_freq / 1000000);

  /* 1. Run Power-On Self-Test (POST) */
  POST_Status_t post_status = POST_RunSelfTest();

  /* 2. Initialize feedback subsystems */
  StatusLED_Init();
  Buttons_Init();
  Beeper_Init();
  lcdInit();
  lcdBacklightOn();
  lcdSetOrientation(LCD_ORIENTATION_LANDSCAPE); // 320x240

  /* 3. Output diagnostic report to UART3 terminal */
  POST_PrintSummary();

  /* 4. Process POST status result */
  if (post_status == POST_ERR_SRAM || post_status == POST_ERR_CCMRAM || post_status == POST_ERR_DISPLAY)
  {
    StatusLED_Set(STATUS_LED_ERROR, STATUS_LED_ON);
    Beeper_ErrorAlert();
  }
  else
  {
    Beeper_BootMelody();
  }

  /* 5. LVGL Initialization (Owned exclusively by this task) */
  LVGL_Port_Init();
  printf("[INIT] LVGL Ready.\r\n");

  /* 6. Full Peripherals Initialization */
  if (W25qxx_Init())
  {
    printf("[INIT] W25QXX Flash Ready.\r\n");
  }
  else
  {
    printf("[INIT] W25QXX Flash FAILED.\r\n");
  }

  if (SDCard_InitSystemDirs())
  {
    printf("[INIT] SD Card FileSystem Ready.\r\n");
  }
  else
  {
    printf("[INIT] SD Card FileSystem FAILED.\r\n");
  }

  /* 7. Spawn InputAudioTask & StorageIoTask in CCM RAM */
  OSTasks_Init();

  /* 7.5. Initialize MCU internal temperature sensor & probe external DS18B20 on PA15 */
  (void)TempSensor_Init();

  /* 7.6. Probe the optional VS1053 audio decoder on SPI2 (P19 header + PA2 XRESET) */
  (void)VS1053_Init(&hspi2);
  AudioPlayer_Init();

  /* 8. Initialize Console UI Manager (Status Bar + Home Dashboard) & USART3 Uploader + CLI */
  UIManager_Init();
  AudioSvc_Init();
  UARTLoader_Init();
  UARTCli_Init();

  /* 8.5. Initialize ESP32-C6 Companion Link on UART4 */
  ESPCompanion_Init();
  (void)ESPCompanion_LoadAndSendWifiFromSD();

  uint32_t last_heartbeat_tick = 0;
  Gui_EventMsg_t gui_evt;

  bool was_app_running = false;

    /* Infinite GUI & Render Loop (~66 FPS / 15ms period) */
  for(;;)
  {
    /* 1. Refresh Watchdog - must be called regardless of whether an app is running */
    HAL_IWDG_Refresh(&hiwdg);

    /* 1.5. Process screenshot hotkey (KEY2 long press, F12/PrtSc, or Select+R1) */
    if (Screenshot_TakeRequest() && !AppLoader_IsRunning())
    {
      char shot_path[64] = {0};
      if (Screenshot_CaptureToSD(shot_path, sizeof(shot_path)))
      {
        printf("[SHOT] Saved screenshot: %s\r\n", shot_path);
      }
    }

    /* 1.8. Poll interactive PC Terminal CLI over USART3 (works both in menu and while app runs) */
    UARTCli_Poll();

    /* 2. If an external .bin app is running in SandboxTask, yield display to it */
    if (AppLoader_IsRunning())
    {
      was_app_running = true;
      if (Screenshot_TakeRequest())
      {
        char shot_path[64] = {0};
        if (Screenshot_CaptureToSD(shot_path, sizeof(shot_path)))
        {
          printf("[SHOT] Saved in-game screenshot: %s\r\n", shot_path);
        }
      }
      ESPCompanion_Poll();
      AppLoader_Service();
      osDelay(20);
      continue;
    }
    else if (was_app_running)

    {
      /* External app just exited! Restore LVGL screen redraw */
      was_app_running = false;
      UIManager_OnAppExit();

      AppLoader_FaultInfo_t fault;
      if (AppLoader_TakeFaultInfo(&fault))
      {
        static char crash_text[96];
        snprintf(crash_text, sizeof(crash_text), "CFSR 0x%08lX\nPC   0x%08lX\nADDR 0x%08lX",
                 (unsigned long)fault.cfsr, (unsigned long)fault.pc, (unsigned long)fault.fault_addr);
        printf("[LOADER] App crashed: %s\r\n", crash_text);
        lv_obj_t *mbox = lv_msgbox_create(NULL, "App crashed", crash_text, NULL, false);
        lv_obj_center(mbox);
        /* With a NULL parent LVGL wraps the box in a dimmed modal backdrop: delete the backdrop */
        lv_obj_del_delayed(lv_obj_get_parent(mbox), 4000);
        Beeper_ErrorAlert();
      }
      else
      {
        Beeper_Click();
      }
    }

    /* 1. Check for completed async events from StorageIoTask */
    while (OSTasks_GetGuiEvent(&gui_evt))
    {
      if (gui_evt.type == GUI_EVT_DIR_READY || gui_evt.type == GUI_EVT_STORAGE_ERROR)
      {
        UIManager_OnDirReady();
      }
    }

    /* 2. Non-blocking Heartbeat on LD0 (1 Hz) & periodic MCU overheat check (0.2 Hz) */
    if ((HAL_GetTick() - last_heartbeat_tick) >= 500)
    {
      last_heartbeat_tick = HAL_GetTick();
      StatusLED_Toggle(STATUS_LED_HEARTBEAT);
      TempSensor_PeriodicMcuCheck();
    }

    /* 3. Check for zero-touch USART3 upload trigger from PC */
    if (UARTLoader_TakeAutoTrigger())
    {
      (void)UARTLoader_RunSession(true);
      if (!AppLoader_IsRunning())
      {
        UIManager_ShowScreen(UI_SCREEN_GAMES);
        lv_obj_invalidate(lv_scr_act());
      }
      continue;
    }

    /* 3.5. Service ESP32-C6 Companion Co-Processor */
    ESPCompanion_Poll();

    char remote_app[64];
    if (ESPCompanion_TakePendingAppRun(remote_app, sizeof(remote_app)))
    {
      size_t rlen = strlen(remote_app);
      bool is_script = (rlen >= 2U && (strcmp(&remote_app[rlen - 2U], ".c") == 0 ||
                                       strcmp(&remote_app[rlen - 2U], ".C") == 0));
      Beeper_Click();
      if (is_script)
      {
        (void)AppLoader_LoadAndRunScript(remote_app);
      }
      else
      {
        (void)AppLoader_LoadAndRun(remote_app);
      }
      if (AppLoader_IsRunning())
      {
        continue;
      }
    }

    /* 4. Update Top Status Bar (RTC Clock & USB/SD indicators) */
    UIManager_Update();

        /* 4. LVGL Graphics Rendering */
        LVGL_Port_HandleFlushConfirmation();
        lv_timer_handler();

        /* 5. Refresh Watchdog */

    HAL_IWDG_Refresh(&hiwdg);

    /* 6. Pause 15ms (~66 FPS frame pacing) */

    osDelay(15);
  }

  /* USER CODE END 5 */
}

void HAL_TIM_PeriodElapsedCallback(TIM_HandleTypeDef *htim)
{
  if (htim->Instance == TIM4)
  {
    HAL_IncTick();
  }
  /* USER CODE BEGIN Callback 1 */
  lv_tick_inc(1);
  /* USER CODE END Callback 1 */
}

void Error_Handler(void)
{
  __disable_irq();
  while (1)
  {
  }
}
